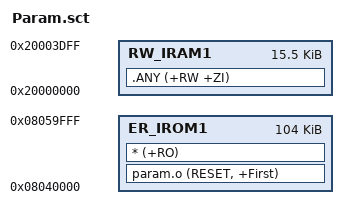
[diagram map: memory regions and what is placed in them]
; *************************************************************
; *** Scatter-Loading Description File generated by uVision ***
; *************************************************************
LR_IROM1 0x08040000 0x01a000  {      ; Load region size_region
    ER_IROM1 0x08040000	0x01a000  {  ; load address = execution address
        param.o (RESET, +First)
        * (+RO)
    }

    RW_IRAM1 0x20000000 0x03e00
    {
       .ANY (+RW +ZI)
    }
}

